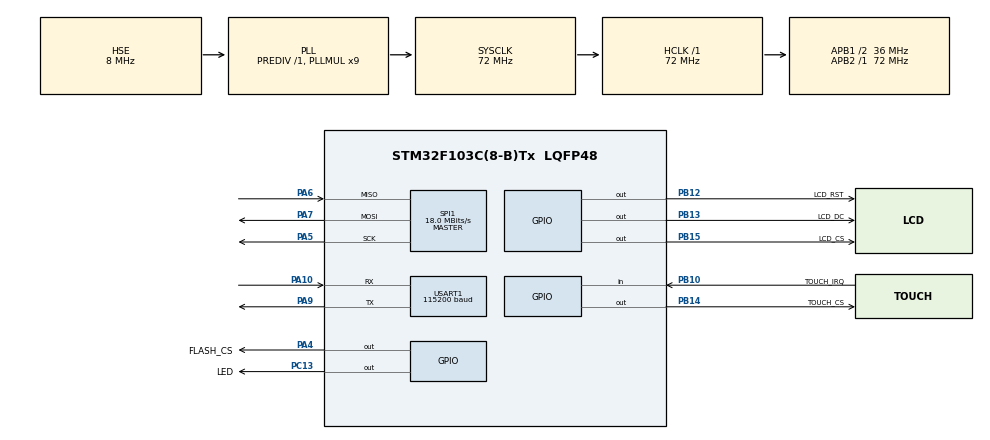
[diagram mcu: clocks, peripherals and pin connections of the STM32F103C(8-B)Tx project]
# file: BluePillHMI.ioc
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Mcu.Family=STM32F1
Mcu.Name=STM32F103C(8-B)Tx
Mcu.Package=LQFP48
NVIC.PriorityGroup=NVIC_PRIORITYGROUP_4
PA10.Mode=Asynchronous
PA10.Signal=USART1_RX
PA13.Mode=Serial_Wire
PA13.Signal=SYS_JTMS-SWDIO
PA14.Mode=Serial_Wire
PA14.Signal=SYS_JTCK-SWCLK
PA4.GPIO_Label=FLASH_CS
PA4.GPIO_Speed=GPIO_SPEED_FREQ_HIGH
PA4.PinState=GPIO_PIN_SET
PA4.Signal=GPIO_Output
PA5.Mode=Full_Duplex_Master
PA5.Signal=SPI1_SCK
PA6.Mode=Full_Duplex_Master
PA6.Signal=SPI1_MISO
PA7.Mode=Full_Duplex_Master
PA7.Signal=SPI1_MOSI
PA9.Mode=Asynchronous
PA9.Signal=USART1_TX
PB10.GPIO_Label=TOUCH_IRQ
PB10.GPIO_PuPd=GPIO_PULLUP
PB10.Signal=GPIO_Input
PB12.GPIO_Label=LCD_RST
PB12.GPIO_Speed=GPIO_SPEED_FREQ_HIGH
PB12.PinState=GPIO_PIN_SET
PB12.Signal=GPIO_Output
PB13.GPIO_Label=LCD_DC
PB13.GPIO_Speed=GPIO_SPEED_FREQ_HIGH
PB13.PinState=GPIO_PIN_SET
PB13.Signal=GPIO_Output
PB14.GPIO_Label=TOUCH_CS
PB14.GPIO_Speed=GPIO_SPEED_FREQ_HIGH
PB14.PinState=GPIO_PIN_SET
PB14.Signal=GPIO_Output
PB15.GPIO_Label=LCD_CS
PB15.GPIO_Speed=GPIO_SPEED_FREQ_HIGH
PB15.PinState=GPIO_PIN_SET
PB15.Signal=GPIO_Output
PC13-TAMPER-RTC.GPIO_Label=LED
PC13-TAMPER-RTC.GPIO_Speed=GPIO_SPEED_FREQ_HIGH
PC13-TAMPER-RTC.PinState=GPIO_PIN_SET
PC13-TAMPER-RTC.Signal=GPIO_Output
PD0-OSC_IN.Mode=HSE-External-Oscillator
PD0-OSC_IN.Signal=RCC_OSC_IN
PD1-OSC_OUT.Mode=HSE-External-Oscillator
PD1-OSC_OUT.Signal=RCC_OSC_OUT
ProjectManager.HeapSize=0x0
ProjectManager.StackSize=0x1000
ProjectManager.TargetToolchain=MDK-ARM V5.32
RCC.AHBFreq_Value=72000000
RCC.APB1CLKDivider=RCC_HCLK_DIV2
RCC.APB1Freq_Value=36000000
RCC.APB1TimFreq_Value=72000000
RCC.APB2Freq_Value=72000000
RCC.APB2TimFreq_Value=72000000
RCC.HCLKFreq_Value=72000000
RCC.HSE_VALUE=8000000
RCC.PLLMUL=RCC_PLL_MUL9
RCC.PLLSourceVirtual=RCC_PLLSOURCE_HSE
RCC.SYSCLKFreq_VALUE=72000000
RCC.SYSCLKSource=RCC_SYSCLKSOURCE_PLLCLK
RCC.USBFreq_Value=72000000
SPI1.BaudRatePrescaler=SPI_BAUDRATEPRESCALER_4
SPI1.CalculateBaudRate=18.0 MBits/s
SPI1.Direction=SPI_DIRECTION_2LINES
SPI1.Mode=SPI_MODE_MASTER
SPI1.VirtualType=VM_MASTER
USART1.BaudRate=115200
USART1.VirtualMode=VM_ASYNC
board=custom

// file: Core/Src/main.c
/* USER CODE BEGIN Header */
/**
  ******************************************************************************
  * @file           : main.c
  * @brief          : Main program body
  ******************************************************************************
  * @attention
  *
  * Copyright (c) 2026 STMicroelectronics.
  * All rights reserved.
  *
  * This software is licensed under terms that can be found in the LICENSE file
  * in the root directory of this software component.
  * If no LICENSE file comes with this software, it is provided AS-IS.
  *
  ******************************************************************************
  */
/* USER CODE END Header */
#include "main.h"
#include "spi.h"
#include "usart.h"
#include "gpio.h"

/* USER CODE BEGIN Includes */
#include "app.h"
#include "board.h"

/* USER CODE END Includes */

void SystemClock_Config(void);

int main(void)
{

  /* MCU Configuration--------------------------------------------------------*/

  /* Reset of all peripherals, Initializes the Flash interface and the Systick. */
  HAL_Init();

  /* Configure the system clock */
  SystemClock_Config();

  /* Initialize all configured peripherals */
  MX_GPIO_Init();
  MX_SPI1_Init();
  MX_USART1_UART_Init();
  /* USER CODE BEGIN 2 */
  app_init();

  /* USER CODE END 2 */

  /* Infinite loop */
  while (1)
  {

    /* USER CODE BEGIN 3 */
    app_tick();
  }
  /* USER CODE END 3 */
}

void SystemClock_Config(void)
{
  RCC_OscInitTypeDef RCC_OscInitStruct = {0};
  RCC_ClkInitTypeDef RCC_ClkInitStruct = {0};

  /** Initializes the RCC Oscillators according to the specified parameters
  * in the RCC_OscInitTypeDef structure.
  */
  RCC_OscInitStruct.OscillatorType = RCC_OSCILLATORTYPE_HSE;
  RCC_OscInitStruct.HSEState = RCC_HSE_ON;
  RCC_OscInitStruct.HSEPredivValue = RCC_HSE_PREDIV_DIV1;
  RCC_OscInitStruct.HSIState = RCC_HSI_ON;
  RCC_OscInitStruct.PLL.PLLState = RCC_PLL_ON;
  RCC_OscInitStruct.PLL.PLLSource = RCC_PLLSOURCE_HSE;
  RCC_OscInitStruct.PLL.PLLMUL = RCC_PLL_MUL9;
  if (HAL_RCC_OscConfig(&RCC_OscInitStruct) != HAL_OK)
  {
    Error_Handler();
  }

  /** Initializes the CPU, AHB and APB buses clocks
  */
  RCC_ClkInitStruct.ClockType = RCC_CLOCKTYPE_HCLK|RCC_CLOCKTYPE_SYSCLK
                              |RCC_CLOCKTYPE_PCLK1|RCC_CLOCKTYPE_PCLK2;
  RCC_ClkInitStruct.SYSCLKSource = RCC_SYSCLKSOURCE_PLLCLK;
  RCC_ClkInitStruct.AHBCLKDivider = RCC_SYSCLK_DIV1;
  RCC_ClkInitStruct.APB1CLKDivider = RCC_HCLK_DIV2;
  RCC_ClkInitStruct.APB2CLKDivider = RCC_HCLK_DIV1;

  if (HAL_RCC_ClockConfig(&RCC_ClkInitStruct, FLASH_LATENCY_2) != HAL_OK)
  {
    Error_Handler();
  }
}

void Error_Handler(void)
{
  /* USER CODE BEGIN Error_Handler_Debug */
  /* User can add his own implementation to report the HAL error return state */
  __disable_irq();
  while (1)
  {
    board_reset_poll();
  }
  /* USER CODE END Error_Handler_Debug */
}
